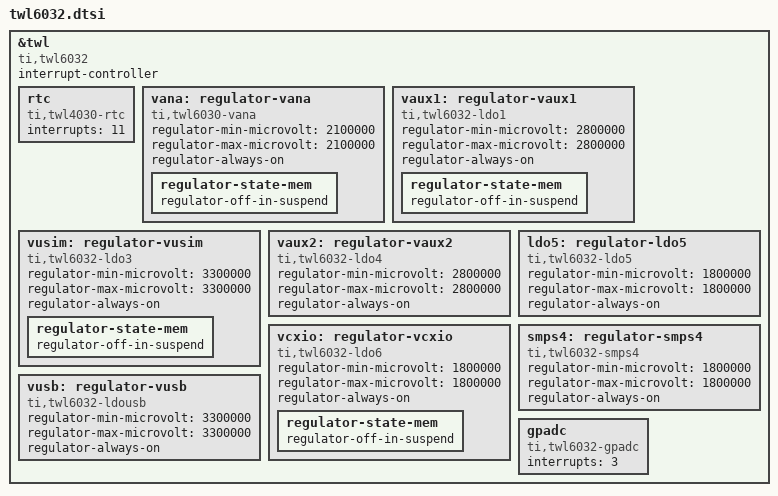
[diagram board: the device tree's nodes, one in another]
/*
 * Integrated Power Management Chip
 * http://www.ti.com/lit/ds/symlink/twl6032.pdf
 */
&twl {
	compatible = "ti,twl6032";
	interrupt-controller;
	#interrupt-cells = <1>;

	rtc {
		compatible = "ti,twl4030-rtc";
		interrupts = <11>;
	};

	vana: regulator-vana {
		compatible = "ti,twl6030-vana";
		regulator-min-microvolt = <2100000>;
		regulator-max-microvolt = <2100000>;
		regulator-always-on;
		regulator-state-mem {
			regulator-off-in-suspend;
		};
	};

	vaux1: regulator-vaux1 {
		compatible = "ti,twl6032-ldo1";
		regulator-min-microvolt = <2800000>;
		regulator-max-microvolt = <2800000>;
		regulator-always-on;
		regulator-state-mem {
			regulator-off-in-suspend;
		};
	};

	vusim: regulator-vusim {
		compatible = "ti,twl6032-ldo3";
		regulator-min-microvolt = <3300000>;
		regulator-max-microvolt = <3300000>;
		regulator-always-on;
		regulator-state-mem {
			regulator-off-in-suspend;
		};
	};

	vaux2: regulator-vaux2 {
		compatible = "ti,twl6032-ldo4";
		regulator-min-microvolt = <2800000>;
		regulator-max-microvolt = <2800000>;
		regulator-always-on;
	};

	ldo5: regulator-ldo5 {
		compatible = "ti,twl6032-ldo5";
		regulator-min-microvolt = <1800000>;
		regulator-max-microvolt = <1800000>;
		regulator-always-on;
	};

	vcxio: regulator-vcxio {
		compatible = "ti,twl6032-ldo6";
		regulator-min-microvolt = <1800000>;
		regulator-max-microvolt = <1800000>;
		regulator-always-on;
		regulator-state-mem {
			regulator-off-in-suspend;
		};
	};

	smps4: regulator-smps4 {
		compatible = "ti,twl6032-smps4";
		regulator-min-microvolt = <1800000>;
		regulator-max-microvolt = <1800000>;
		regulator-always-on;
	};

	vusb: regulator-vusb {
		compatible = "ti,twl6032-ldousb";
		regulator-min-microvolt = <3300000>;
		regulator-max-microvolt = <3300000>;
		regulator-always-on;
	};

	gpadc: gpadc {
		compatible = "ti,twl6032-gpadc";
		interrupts = <3>;
		#io-channel-cells = <1>;
	};
};
